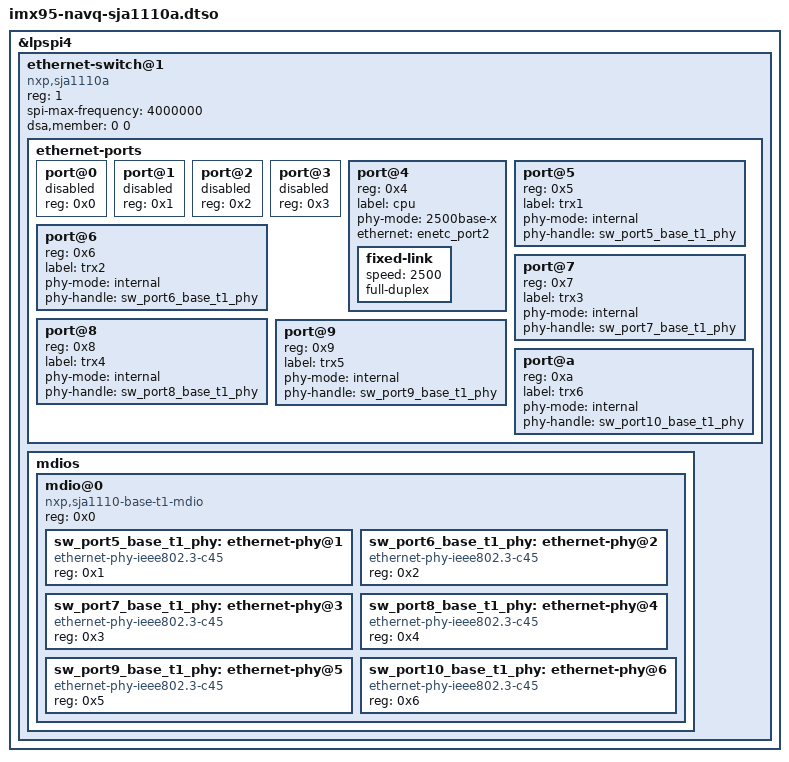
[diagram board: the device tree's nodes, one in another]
// SPDX-License-Identifier: (GPL-2.0+ OR MIT)
/*
 * Copyright 2026 NXP
 *
 * DT overlay for MR-NAVQ95E-T1S expansion board
 */

/dts-v1/;
/plugin/;

&lpspi4 {
	#address-cells = <1>;
	#size-cells = <0>;

	ethernet-switch@1 {
		compatible = "nxp,sja1110a";
		reg = <1>;
		spi-max-frequency = <4000000>;
		dsa,member = <0 0>;

		ethernet-ports {
			#address-cells = <1>;
			#size-cells = <0>;

			/* microcontroller - unused */
			port@0 {
				reg = <0x0>;
				status = "disabled";
			};

			/* TODO: TJA1 (TJA1120) */
			port@1 {
				reg = <0x1>;
				status = "disabled";
			};

			/* TODO: TJA2 (TJA1120) */
			port@2 {
				reg = <0x2>;
				status = "disabled";
			};

			/* unconnected */
			port@3 {
				reg = <0x3>;
				status = "disabled";
			};

			/* ENETC2 */
			port@4 {
				reg = <0x4>;
				label = "cpu";
				phy-mode = "2500base-x";
				ethernet = <&enetc_port2>;

				fixed-link {
					speed = <2500>;
					full-duplex;
				};
			};

			/* 100BASE-T1 (5-10) */
			port@5 {
				reg = <0x5>;
				label = "trx1";
				phy-mode = "internal";
				phy-handle = <&sw_port5_base_t1_phy>;
			};

			port@6 {
				reg = <0x6>;
				label = "trx2";
				phy-mode = "internal";
				phy-handle = <&sw_port6_base_t1_phy>;
			};

			port@7 {
				reg = <0x7>;
				label = "trx3";
				phy-mode = "internal";
				phy-handle = <&sw_port7_base_t1_phy>;
			};

			port@8 {
				reg = <0x8>;
				label = "trx4";
				phy-mode = "internal";
				phy-handle = <&sw_port8_base_t1_phy>;
			};

			port@9 {
				reg = <0x9>;
				label = "trx5";
				phy-mode = "internal";
				phy-handle = <&sw_port9_base_t1_phy>;
			};

			port@a {
				reg = <0xa>;
				label = "trx6";
				phy-mode = "internal";
				phy-handle = <&sw_port10_base_t1_phy>;
			};
		};

		mdios {
			#address-cells = <1>;
			#size-cells = <0>;

			mdio@0 {
				compatible = "nxp,sja1110-base-t1-mdio";
				reg = <0x0>;
				#address-cells = <1>;
				#size-cells = <0>;

				sw_port5_base_t1_phy: ethernet-phy@1 {
					compatible = "ethernet-phy-ieee802.3-c45";
					reg = <0x1>;
				};

				sw_port6_base_t1_phy: ethernet-phy@2 {
					compatible = "ethernet-phy-ieee802.3-c45";
					reg = <0x2>;
				};

				sw_port7_base_t1_phy: ethernet-phy@3 {
					compatible = "ethernet-phy-ieee802.3-c45";
					reg = <0x3>;
				};

				sw_port8_base_t1_phy: ethernet-phy@4 {
					compatible = "ethernet-phy-ieee802.3-c45";
					reg = <0x4>;
				};

				sw_port9_base_t1_phy: ethernet-phy@5 {
					compatible = "ethernet-phy-ieee802.3-c45";
					reg = <0x5>;
				};

				sw_port10_base_t1_phy: ethernet-phy@6 {
					compatible = "ethernet-phy-ieee802.3-c45";
					reg = <0x6>;
				};
			};
		};
	};
};
